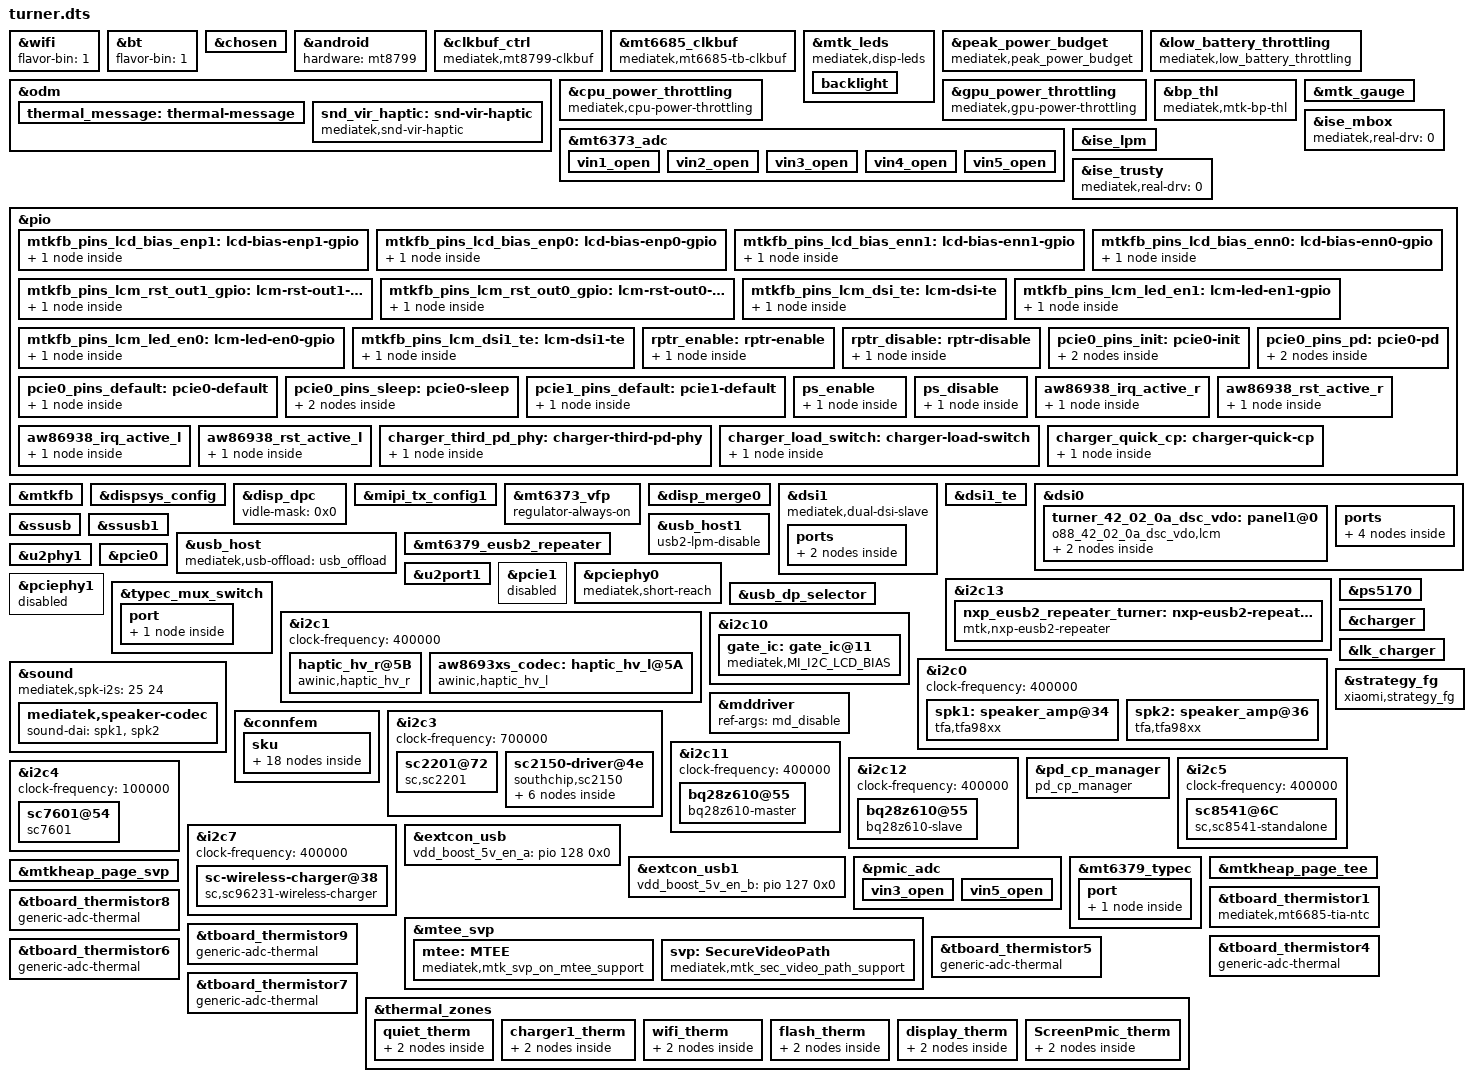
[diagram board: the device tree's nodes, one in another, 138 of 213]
// SPDX-License-Identifier: (GPL-2.0 OR MIT)
/*
 * Copyright (C) 2022 MediaTek Inc.
 */
/dts-v1/;
/plugin/;
&wifi {
	flavor-bin = "1";
};

&bt {
	flavor-bin = "1";
};

#include <dt-bindings/interrupt-controller/arm-gic.h>
#include <dt-bindings/interrupt-controller/irq.h>
#include <dt-bindings/phy/phy.h>
#include <dt-bindings/pinctrl/mt6991-pinfunc.h>
#include <dt-bindings/power/mt6991-power.h>
#include "mediatek/turner-mt6991-common.dtsi"
#include "mediatek/turner-sensor-common.dtsi"
#include <dt-bindings/iio/mt635x-auxadc.h>
#include <dt-bindings/thermal/thermal.h>
#include <dt-bindings/gpio/gpio.h>

&chosen {
bootargs_ext = "rcu_nocbs=0-7 \
		log_buf_len=4M";
bootargs_ext_fac = "cpufreq.default_governor=conservative \
		rcu_nocbs=0-7 \
		log_buf_len=4M";
};

&android {
	hardware = "mt8799";
};

&clkbuf_ctrl {
	compatible = "mediatek,mt8799-clkbuf";
};

&mt6685_clkbuf {
	compatible = "mediatek,mt6685-tb-clkbuf";
};

&mtk_leds {
	compatible = "mediatek,disp-leds";

	backlight {
		max-brightness = <4095>;
		min-brightness = <1>;
		max-hw-brightness = <2047>;
		led-mode = <4>;
		default-state = "FourteenPercent";
	};
};

&odm {
	thermal_message: thermal-message {
		board-sensor = "VIRTUAL-SENSOR";
		board-sensor-trip-enable = <1>;
		trip-point-high = <41000>;
		trip-point-low = <40000>;
	};
};

&peak_power_budget {
	compatible = "mediatek,peak_power_budget";

	battery-circult-rdc = <17>;
	battery0-path-rac-t0 = <35>;
	battery0-path-rac-t1 = <35>;
	battery0-path-rac-t2 = <35>;
	battery0-path-rac-t3 = <35>;
	battery0-path-rac-t4 = <35>;
	battery0-path-rac-t5 = <35>;

	system-uvlo = <2610>;

	max-temperature-stage = <5>;
	temperature-threshold = <25 10 0 0xFFFFFFF6 0xFFFFFFEC>;

	bat-ocv-table-num = <0>;
};

&low_battery_throttling {
		compatible = "mediatek,low_battery_throttling";
		lvsys-thd-enable = <1>;
		vbat-thd-enable = <1>;
		bat0-thd-volts-l = <
			3475 3200 3050
			3480 3200 3050
			3509 3200 3050
			3641 3200 3050
			3673 3200 3050>;
		bat0-thd-volts-h = <
			3575 3475 3200
			3580 3480 3200
			3609 3509 3200
			3741 3641 3200
			3773 3673 3200>;
		bat1-thd-volts-l = <
			3475 3200 3050
			3480 3200 3050
			3509 3200 3050
			3641 3200 3050
			3673 3200 3050>;
		bat1-thd-volts-h = <
			3575 3475 3200
			3580 3480 3200
			3609 3509 3200
			3741 3641 3200
			3773 3673 3200>;
		lvsys-thd-volt-l = <3050>;
		lvsys-thd-volt-h = <3200>;
		temperature-stage-threshold = <25 10 0 0xFFFFFFF6>;

		throttle-level = <0 1 2 3>,
			<0 1 2 3>,
			<0 1 2 3>,
			<0 1 2 3>,
			<0 1 2 3>;
};

&cpu_power_throttling {
	compatible = "mediatek,cpu-power-throttling";

	lbat-max-level = <3>;
	lbat-limit-freq-lv1 = < 1400000  1800000 2200000>;
	lbat-limit-freq-lv2 = < 1200000  120000  120000>;
	lbat-limit-freq-lv3 = < 330000   550000  670000>;

	oc-max-level = <2>;
	oc-limit-freq-lv1 = < 2147483647  2147483647 2147483647>;
	oc-limit-freq-lv2 = < 1200000  1700000 1900000>;

	soc-max-level = <3>;
	soc-core-active-lv1 = < 1 1 1 1 1 1 1 1 >;
	soc-core-active-lv2 = < 1 1 1 1 1 1 1 1 >;
	soc-core-active-lv3 = < 1 1 1 1 1 1 0 0 >;
	soc-limit-freq-lv1 = < 2147483647  2147483647 2147483647 >;
	soc-limit-freq-lv2 = < 1400000 1800000 2200000>;
	soc-limit-freq-lv3 = < 1800000 900000  670000>;
};

&gpu_power_throttling {
	compatible = "mediatek,gpu-power-throttling";

	lbat-max-level = <3>;
	lbat-limit-freq-lv1 = <754000>;
	lbat-limit-freq-lv2 = <754000>;
	lbat-limit-freq-lv3 = <338000>;

	oc-max-level = <2>;
	oc-limit-freq-lv1 = <988000>;
	oc-limit-freq-lv2 = <572000>;

	soc-max-level = <3>;
	soc-limit-freq-lv1 = <2147483647>;
	soc-limit-freq-lv2 = <754000>;
	soc-limit-freq-lv3 = <338000>;
};

&bp_thl{
	compatible = "mediatek,mtk-bp-thl";

	max-throttle-level = <3>;
	soc-throttle-level = <0 1 1 2>, //temperature stage 0
					<0 1 1 2>, //temperature stage 1
					<0 1 1 2>, //temperature stage 2
					<0 1 3 3>; //temperature stage 3

	soc-max-stage = <3>;
	soc-limit-threshold = <15 7 5>;

	temperature-max-stage = <3>;
	temperature-stage-threshold = <25 10 0>;

	md-soc-throttle-l = <20>;
	md-soc-throttle-h = <25>;
};

&mtk_gauge {
	DISABLE_MTKBATTERY = <(1)>;
	FIXED_BATTERY_TEMPERATURE = <25>;
	#include "turner_mt6991_battery_table.dtsi"
};

&mt6373_adc {
	vin1_open {
		channel = <AUXADC_VIN1>;
		pures = <ADC_PURES_100K>;
	};
	vin2_open {
		channel = <AUXADC_VIN2>;
		pures = <ADC_PURES_100K>;
	};
	vin3_open {
		channel = <AUXADC_VIN3>;
		pures = <ADC_PURES_100K>;
	};
	vin4_open {
		channel = <AUXADC_VIN4>;
		pures = <ADC_PURES_100K>;
	};
	vin5_open {
		channel = <AUXADC_VIN5>;
		pures = <ADC_PURES_100K>;
	};
};

&ise_mbox {
	mediatek,real-drv = <0>;
};

&ise_lpm {
	ise-wakelock = <0>;
	ise-lpm-freerun = <0>;
	ise-lpm-deinit-bypass = <0>;
};

&ise_trusty {
	mediatek,real-drv = <0>;
};

&pio {
	mtkfb_pins_lcd_bias_enp1: lcd-bias-enp1-gpio {
		pins-cmd-dat {
			pinmux = <PINMUX_GPIO103__FUNC_GPIO103>;
			slew-rate = <1>;
			output-high;
		};
	};

	mtkfb_pins_lcd_bias_enp0: lcd-bias-enp0-gpio {
		pins-cmd-dat {
			pinmux = <PINMUX_GPIO103__FUNC_GPIO103>;
			slew-rate = <1>;
			output-low;
		};
	};

	mtkfb_pins_lcd_bias_enn1: lcd-bias-enn1-gpio {
		pins-cmd-dat {
			pinmux = <PINMUX_GPIO103__FUNC_GPIO103>;
			slew-rate = <1>;
			output-high;
		};
	};

	mtkfb_pins_lcd_bias_enn0: lcd-bias-enn0-gpio {
		pins-cmd-dat {
			pinmux = <PINMUX_GPIO103__FUNC_GPIO103>;
			slew-rate = <1>;
			output-low;
		};
	};

	mtkfb_pins_lcm_rst_out1_gpio: lcm-rst-out1-gpio {
		pins-cmd-dat {
			pinmux = <PINMUX_GPIO90__FUNC_GPIO90>;
			slew-rate = <1>;
			output-high;
		};
	};

	mtkfb_pins_lcm_rst_out0_gpio: lcm-rst-out0-gpio {
		pins-cmd-dat {
			pinmux = <PINMUX_GPIO90__FUNC_GPIO90>;
			slew-rate = <1>;
			output-low;
		};
	};
	mtkfb_pins_lcm_dsi_te: lcm-dsi-te {
		pins-cmd-dat {
			pinmux = <PINMUX_GPIO89__FUNC_DSI_TE>;
		};
	};

	mtkfb_pins_lcm_led_en1: lcm-led-en1-gpio {
		pins-cmd-dat {
			pinmux = <PINMUX_GPIO174__FUNC_GPIO174>;
			slew-rate = <1>;
			output-high;
		};
	};

	mtkfb_pins_lcm_led_en0: lcm-led-en0-gpio {
		pins-cmd-dat {
			pinmux = <PINMUX_GPIO174__FUNC_GPIO174>;
			slew-rate = <1>;
			output-low;
		};
	};

	mtkfb_pins_lcm_dsi1_te: lcm-dsi1-te {
		pins-cmd-dat {
			pinmux = <PINMUX_GPIO6__FUNC_DSI1_TE>;
		};
	};
};

&mtkfb {
	pinctrl-names = "lcd_bias_enp1_gpio", "lcd_bias_enp0_gpio",
		"lcd_bias_enn1_gpio", "lcd_bias_enn0_gpio",
		"lcm_rst_out1_gpio", "lcm_rst_out0_gpio",
		"mode_te_te", "lcm_led_en1_gpio", "lcm_led_en0_gpio";
	pinctrl-0 = <&mtkfb_pins_lcd_bias_enp1>;
	pinctrl-1 = <&mtkfb_pins_lcd_bias_enp0>;
	pinctrl-2 = <&mtkfb_pins_lcd_bias_enn1>;
	pinctrl-3 = <&mtkfb_pins_lcd_bias_enn0>;
	pinctrl-4 = <&mtkfb_pins_lcm_rst_out1_gpio>;
	pinctrl-5 = <&mtkfb_pins_lcm_rst_out0_gpio>;
	pinctrl-6 = <&mtkfb_pins_lcm_dsi_te>;
	pinctrl-7 = <&mtkfb_pins_lcm_led_en1>;
	pinctrl-8 = <&mtkfb_pins_lcm_led_en0>;
	pinctrl-9 = <&mtkfb_pins_lcm_dsi1_te>;

	status = "okay";
};

&dispsys_config {
	pinctrl-names = "mode_te_te";
	pinctrl-0 = <&mtkfb_pins_lcm_dsi_te>;
	pinctrl-1 = <&mtkfb_pins_lcm_dsi1_te>;

	is-tablet;
	status = "okay";
	lk_mode_index = <0>;
//	enable-discrete-path = <1>;
	helper-value = <0>, /*MTK_DRM_OPT_STAGE*/
		<1>, /*MTK_DRM_OPT_USE_CMDQ*/
		<1>, /*MTK_DRM_OPT_USE_M4U*/
		<1>, /*MTK_DRM_OPT_MMQOS_SUPPORT*/
		<1>, /*MTK_DRM_OPT_MMDVFS_SUPPORT*/
		<0>, /*MTK_DRM_OPT_SODI_SUPPORT*/
		<1>, /*MTK_DRM_OPT_IDLE_MGR*/
		<0>, /*MTK_DRM_OPT_IDLEMGR_SWTCH_DECOUPLE*/
		<0>, /*MTK_DRM_OPT_IDLEMGR_BY_REPAINT*/
		<0>, /*MTK_DRM_OPT_IDLEMGR_ENTER_ULPS*/
		<0>, /*MTK_DRM_OPT_IDLEMGR_KEEP_LP11*/
		<0>, /*MTK_DRM_OPT_DYNAMIC_RDMA_GOLDEN_SETTING*/
		<1>, /*MTK_DRM_OPT_IDLEMGR_DISABLE_ROUTINE_IRQ*/
		<1>, /*MTK_DRM_OPT_IDLEMGR_ASYNC*/
		<0>, /*MTK_DRM_OPT_MET_LOG*/
		<1>, /*MTK_DRM_OPT_USE_PQ*/
		<1>, /*MTK_DRM_OPT_ESD_CHECK_RECOVERY*/
		<1>, /*MTK_DRM_OPT_ESD_CHECK_SWITCH*/
		<1>, /*MTK_DRM_OPT_PRESENT_FENCE*/
		<0>, /*MTK_DRM_OPT_RDMA_UNDERFLOW_AEE*/
		<1>, /*MTK_DRM_OPT_DSI_UNDERRUN_AEE*/
		<0>, /*MTK_DRM_OPT_ODDMR_UNDERRUN_AEE*/
		<1>, /*MTK_DRM_OPT_HRT*/
		<0>, /*MTK_DRM_OPT_HRT_MODE*/
		<0>, /*MTK_DRM_OPT_DELAYED_TRIGGER*/
		<0>, /*MTK_DRM_OPT_OVL_EXT_LAYER*/
		<0>, /*MTK_DRM_OPT_AOD*/
		<1>, /*MTK_DRM_OPT_RPO*/
		<1>, /*MTK_DRM_OPT_DUAL_PIPE*/
		<0>, /*MTK_DRM_OPT_DC_BY_HRT*/
		<1>, /*MTK_DRM_OPT_OVL_WCG*/
		<0>, /*MTK_DRM_OPT_OVL_SBCH*/
		<1>, /*MTK_DRM_OPT_COMMIT_NO_WAIT_VBLANK*/
		<0>, /*MTK_DRM_OPT_MET*/
		<0>, /*MTK_DRM_OPT_REG_PARSER_RAW_DUMP*/
		<0>, /*MTK_DRM_OPT_VP_PQ*/
		<0>, /*MTK_DRM_OPT_GAME_PQ*/
		<0>, /*MTK_DRM_OPT_MMPATH*/
		<0>, /*MTK_DRM_OPT_HBM*/
		<0>, /*MTK_DRM_OPT_VDS_PATH_SWITCH*/
		<0>, /*MTK_DRM_OPT_LAYER_REC*/
		<1>, /*MTK_DRM_OPT_CLEAR_LAYER*/
		<0>, /*MTK_DRM_OPT_LFR*/
		<0>, /*MTK_DRM_OPT_SF_PF*/
		<0>, /*MTK_DRM_OPT_DYN_MIPI_CHANGE*/
		<1>, /*MTK_DRM_OPT_PRIM_DUAL_PIPE*/
		<0>, /*MTK_DRM_OPT_MSYNC2_0*/
		<0>, /*MTK_DRM_OPT_MSYNC2_0_WAIT_EPT*/
		<1>, /*MTK_DRM_OPT_MML_PRIMARY*/
		<1>, /*MTK_DRM_OPT_MML_SUPPORT_CMD_MODE*/
		<1>, /*MTK_DRM_OPT_MML_PQ*/
		<1>, /*MTK_DRM_OPT_MML_IR*/
		<0>, /*MTK_DRM_OPT_DUAL_TE*/
		<0>, /*MTK_DRM_OPT_RES_SWITCH*/
		<1>, /*MTK_DRM_OPT_RES_SWITCH_ON_AP*/
		<0>, /*MTK_DRM_OPT_PREFETCH_TE*/
		<0>, /*MTK_DRM_OPT_VIDLE_APSRC_OFF*/
		<0>, /*MTK_DRM_OPT_VIDLE_DSI_PLL_OFF*/
		<0>, /*MTK_DRM_OPT_CHECK_TRIGGER_MERGE*/
		<0>, /*MTK_DRM_OPT_VIRTUAL_DISP*/
		<1>, /*MTK_DRM_OPT_OVL_BW_MONITOR*/
		<0>, /*MTK_DRM_OPT_GPU_CACHE*/
		<1>, /*MTK_DRM_OPT_SPHRT*/
		<0>, /*MTK_DRM_OPT_SDPA_OVL_SWITCH*/
		<1>, /*MTK_DRM_OPT_HRT_BY_LARB*/
		<0>, /*MTK_DRM_OPT_TILE_OVERHEAD*/
		<0>, /*MTK_DRM_OPT_VIDLE_TOP_EN*/
		<0>, /*MTK_DRM_OPT_VIDLE_MTCMOS_DT_EN*/
		<0>, /*MTK_DRM_OPT_VIDLE_MMINFRA_DT_EN*/
		<0>, /*MTK_DRM_OPT_VIDLE_DVFS_DT_EN*/
		<0>, /*MTK_DRM_OPT_VIDLE_QOS_DT_EN*/
		<0>, /*MTK_DRM_OPT_VIDLE_GCE_TS_EN*/
		<0>, /*MTK_DRM_OPT_VIDLE_FULL_SCENARIO*/
		<0>, /*MTK_DRM_OPT_DPC_PRE_TE_EN*/
		<1>, /*MTK_DRM_OPT_PARTIAL_UPDATE*/
		<0>, /*MTK_DRM_OPT_SLC_ALL_CACHE*/
		<1>, /*MTK_DRM_OPT_OVL_WCG_BY_COLOR_MODE*/
		<0>, /*"MTK_DRM_OPT_OVLSYS_CASCADE"*/
		<1>; /*MTK_DRM_OPT_LTPO_VM*/
};

&disp_dpc {
	vidle-mask = <0x0>;
};

&mipi_tx_config1 {
	status = "okay";
};

&mt6373_vfp {
	regulator-always-on;
};

&disp_merge0 {
	status = "okay";
};

&dsi1 {
	mediatek,dual-dsi-slave;
	status = "okay";
	ports {
		#address-cells = <1>;
		#size-cells = <0>;
		port@1 {
			reg = <1>;
			slave_in: endpoint {
				remote-endpoint = <&master_out>;
			};
		};
	};
};

&dsi1_te {
	interrupt-parent = <&pio>;
	interrupts = <6 1 6 1>;
	status = "okay";
};

&dsi0 {
	status = "okay";
	#address-cells = <1>;
	#size-cells = <0>;
	turner_42_02_0a_dsc_vdo: panel1@0 {
		compatible = "o88_42_02_0a_dsc_vdo,lcm";
		reg = <0>;
		reset-gpios = <&pio 90 0>;
		mi,esd-err-irq-gpio = <&pio 22 0x2002>;
		mi,esd-err-irq-gpio-second = <&pio 21 0x2002>;
		lane-swap-setting = <1 2 0 3 4 2>;
		pn-swap-setting = <1 1 1 1 1 1>;
		pinctrl-names = "default";
		vcn18io-supply = <&mt6373_vcn18io>;
		hw_en-gpios = <&pio 181 0>;
		bias_enp-gpios = <&pio 187 0>;
		bias_enn-gpios = <&pio 206 0>;
		lcm_id-gpios = <&pio 180 (GPIO_ACTIVE_HIGH | GPIO_PULL_UP)>;
		port {
			panel_in: endpoint {
				remote-endpoint = <&dsi_out>;
			};
		};
	};

	ports {
		#address-cells = <1>;
		#size-cells = <0>;
		port@0 {
			reg = <0>;
			dsi_out: endpoint {
				remote-endpoint = <&panel_in>;
			};
		};
		port@1 {
			reg = <1>;
			master_out: endpoint {
				remote-endpoint = <&slave_in>;
			};
		};
	};
};

&pio {

	rptr_enable: rptr-enable {
		pins-cmd-dat {
			pinmux = <PINMUX_GPIO28__FUNC_GPIO28>;
			output-high;
		};
	};

	rptr_disable: rptr-disable {
		pins-cmd-dat {
			pinmux = <PINMUX_GPIO28__FUNC_GPIO28>;
			output-low;
		};
	};

};

&ssusb {
	mediatek,force-vbus;
	mediatek,clk-mgr;
	mediatek,usb3-drd;
	mediatek,uds = <&usb_dp_selector 19>;
	mediatek,eusb2-cm-l1 = <0x474>;
	maximum-speed = "super-speed";
	maximum-speed-host = <0x05>;
	usb-role-switch;
	status = "okay";
};

&ssusb1 {
	wakeup-source;
	mediatek,clk-mgr;
	mediatek,force-vbus;
	mediatek,eusb2-cm-l1 = <0x474>;
	maximum-speed = "high-speed";
	usb-role-switch;
	status = "okay";
};

&usb_host {
	mediatek,usb-offload = <&usb_offload>;
	status = "okay";
};

&usb_host1 {
	usb2-lpm-disable;
	status = "okay";
};

&mt6379_eusb2_repeater {
	mediatek,vrt-sel = <0>;
	mediatek,intr-ofs = "0";
	mediatek,term-ofs = "0";
	mediatek,equalization = <4>;
	mediatek,rx-sqth = <5>;
	mediatek,discth = <0xf>;
	mediatek,host-vrt-sel = <2>;
	mediatek,host-rx-sqth = <0>;
	mediatek,host-discth = <0xf>;
	mediatek,host-term-ofs = "-3";
	mediatek,host-intr-ofs = "4";
	mediatek,pre-emphasis = <2>;
	status = "okay";
};


&i2c13 {

	nxp_eusb2_repeater_turner: nxp-eusb2-repeater-turner@43 {
		compatible = "mtk,nxp-eusb2-repeater";
		pinctrl-names = "enable", "disable";
		pinctrl-0 = <&rptr_enable>;
		pinctrl-1 = <&rptr_disable>;
		reg = <0x43>;
		#phy-cells = <0>;
		status = "okay";
	};

};

&nxp_eusb2_repeater_turner {
	mediatek,rptr-ouput-swing = <0x4>;
	mediatek,rptr-demphasis = <0x22>;
};

&u2phy1 {
	phy-cells = <1>;
	phys = <&nxp_eusb2_repeater_turner>;
	status = "okay";

};

&u2port1 {

	status = "okay";

};

&pcie0 {
	pinctrl-names = "init", "default", "sleep", "pd";
	pinctrl-0 = <&pcie0_pins_init>;
	pinctrl-1 = <&pcie0_pins_default>;
	pinctrl-2 = <&pcie0_pins_sleep>;
	pinctrl-3 = <&pcie0_pins_pd>;
	max-link-speed = <4>;
	status = "okay";
};

&pcie1 {
	pinctrl-names = "default";
	pinctrl-0 = <&pcie1_pins_default>;
	max-link-speed = <4>;
	status = "disabled";
};

&pciephy0 {
	mediatek,short-reach;
	status = "okay";
};

&pciephy1 {
	status = "disabled";
};

/* PCIe pinmux start */
/* skyhawk use waken to control DFD_EN, PCIe0 don't need to control it */
&pio {
	pcie0_pins_init: pcie0-init {
		pins-cmd-dat {
			pinmux = <PINMUX_GPIO241__FUNC_GPIO241>;
			output-low;
		};

		pins-cmd-dat1 {
			pinmux = <PINMUX_GPIO243__FUNC_GPIO243>;
			bias-pull-up;
			input-enable;
		};
	};

	pcie0_pins_default: pcie0-default {
		pins-cmd-dat {
			pinmux = <PINMUX_GPIO241__FUNC_PCIE_PERSTN>,
				 <PINMUX_GPIO243__FUNC_PCIE_CLKREQN>;
			bias-pull-up;
		};
	};

	pcie0_pins_sleep: pcie0-sleep {
		pins-cmd-dat {
			pinmux = <PINMUX_GPIO241__FUNC_GPIO241>;
			output-low;
		};

		pins-cmd-dat1 {
			pinmux = <PINMUX_GPIO243__FUNC_GPIO243>;
			bias-pull-up;
			input-enable;
		};
	};

	pcie0_pins_pd: pcie0-pd {
		pins-cmd-dat {
			pinmux = <PINMUX_GPIO241__FUNC_GPIO241>;
			output-low;
		};

		pins-cmd-dat1 {
			pinmux = <PINMUX_GPIO243__FUNC_GPIO243>;
			bias-pull-down;
			input-enable;
		};
	};

	pcie1_pins_default: pcie1-default {
		pins-cmd-dat {
			pinmux = <PINMUX_GPIO145__FUNC_PCIE_WAKEN_1P>,
				 <PINMUX_GPIO146__FUNC_PCIE_PERSTN_1P>,
				 <PINMUX_GPIO147__FUNC_PCIE_CLKREQN_1P>;
			bias-pull-up = <MTK_PUPD_SET_R1R0_01>;
		};
	};
};
/* PCIe pinmux end */

#if 0
/* no need set here, 6686 will control elna automatically */
/* GPS GPIO standardization start */
&pio {
	gps_pins_default: gps_default {
	};
	gps_l1_lna_pins_ol: gps-l1-lna0 {
		pins-cmd-dat {
			pinmux = <PINMUX_GPIO12__FUNC_GPIO12>;
			output-low;
		};
	};
	gps_l1_lna_pins_dsp_ctrl: gps-l1-lna1 {
		pins-cmd-dat {
			pinmux = <PINMUX_GPIO12__FUNC_GPS_L1_ELNA_EN>;
		};
	};
	gps_l1_lna_pins_oh: gps-l1-lna2 {
		pins-cmd-dat {
			pinmux = <PINMUX_GPIO12__FUNC_GPIO12>;
			output-high;
		};
	};
	gps_l5_lna_pins_ol: gps-l5-lna0 {
		pins-cmd-dat {
			pinmux = <PINMUX_GPIO13__FUNC_GPIO13>;
			output-low;
		};
	};
	gps_l5_lna_pins_dsp_ctrl: gps-l5-lna1 {
		pins-cmd-dat {
			pinmux = <PINMUX_GPIO13__FUNC_GPS_L5_ELNA_EN>;
		};
	};
	gps_l5_lna_pins_oh: gps-l5-lna2 {
		pins-cmd-dat {
			pinmux = <PINMUX_GPIO13__FUNC_GPIO13>;
			output-high;
		};
	};
};
&gps {
	pinctrl-names = "default",
		"gps_l1_lna_disable",
		"gps_l1_lna_dsp_ctrl",
		"gps_l1_lna_enable",
		"gps_l5_lna_disable",
		"gps_l5_lna_dsp_ctrl",
		"gps_l5_lna_enable";
	pinctrl-0 = <&gps_pins_default>;
	pinctrl-1 = <&gps_l1_lna_pins_ol>;
	pinctrl-2 = <&gps_l1_lna_pins_dsp_ctrl>;
	pinctrl-3 = <&gps_l1_lna_pins_oh>;
	pinctrl-4 = <&gps_l5_lna_pins_ol>;
	pinctrl-5 = <&gps_l5_lna_pins_dsp_ctrl>;
	pinctrl-6 = <&gps_l5_lna_pins_oh>;
	status = "okay";
};
/* GPS GPIO standardization end */
#endif

/* usb typec mux start */
&pio {

	ps_enable: ps_enable {
		pins-cmd-dat {
			pinmux = <PINMUX_GPIO207__FUNC_GPIO207>;
			output-high;
		};
	};

	ps_disable: ps_disable {
		pins-cmd-dat {
			pinmux = <PINMUX_GPIO207__FUNC_GPIO207>;
			output-low;
		};
	};

};

&typec_mux_switch {
	orientation-switch;
	mode-switch;
	accessory;
	port {
		ssusb_mux: endpoint {
			remote-endpoint = <&tcpc_typec_usb>;
		};
	};
};

&ps5170 {
	pinctrl-names = "enable", "disable";
	pinctrl-0 = <&ps_enable>;
	pinctrl-1 = <&ps_disable>;
	status = "okay";
};

&usb_dp_selector {
	status = "okay";
};
/* usb typec mux end */

&pio {
	aw86938_irq_active_r:aw86938_irq_active_r {
		pins_cmd_dat {
			pinmux = <PINMUX_GPIO5__FUNC_GPIO5>;
			slew-rate = <0>;
			bias-pull-up = <00>;
		};
	};
	aw86938_rst_active_r:aw86938_rst_active_r {
		pins_cmd_dat {
			pinmux = <PINMUX_GPIO42__FUNC_GPIO42>;
			slew-rate = <0>;
			bias-pull-up = <00>;
		};
	};
	aw86938_irq_active_l:aw86938_irq_active_l {
		pins_cmd_dat {
			pinmux = <PINMUX_GPIO11__FUNC_GPIO11>;
			slew-rate = <0>;
			bias-pull-up = <00>;
		};
	};
	aw86938_rst_active_l:aw86938_rst_active_l {
		pins_cmd_dat {
			pinmux = <PINMUX_GPIO41__FUNC_GPIO41>;
			slew-rate = <0>;
			bias-pull-up = <00>;
		};
	};
};

&i2c1 {
    clock-frequency = <400000>;
	status = "ok";
	haptic_hv_r@5B {
		compatible = "awinic,haptic_hv_r";
		reg = <0x5B>;
		#sound-dai-cells = <0>;
		sound-name-prefix = "HAPTIC_SPK_R";
		irq-gpio = <&pio 11 1>;
		reset-gpio = <&pio 41 1>;
		f0_pre = < 1700 >;
		mode = /bits/ 8 < 5 >;
		aw8693x_f0_cali_percent = /bits/ 8 < 15 >;
		aw8693x_gain_bypass = /bits/ 8 < 1 >;
		aw8693x_uvlo_vol_default = /bits/ 8 < 0 >;
		aw8693x_cont_smart_loop = /bits/ 8 < 0 >;
		aw8693x_cont_drv1_lvl = /bits/ 8 < 0x7F >;
		aw8693x_cont_drv2_lvl = /bits/ 8 < 0x38 >;
		aw8693x_cont_lra_vrms = < 1000 >;
		aw8693x_cont_drv1_time = /bits/ 8 < 0x04 >;
		aw8693x_cont_drv2_time = /bits/ 8 < 0x32 >;
		aw8693x_cont_track_margin = /bits/ 8 < 0x0F >;
		aw8693x_cont_brk_gain = /bits/ 8 < 0x08 >;
		aw8693x_cont_brk_time = /bits/ 8 < 0x08 >;
		aw8693x_duration_time = /bits/ 8 < 20 30 60 >;
		aw8693x_d2s_gain = /bits/ 8 < 0x04 >;
		aw8693x_algo_d2s_gain = /bits/ 8 < 0x01 >;
		aw8693x_drv_width = /bits/ 8 < 0x6A >;
		aw8693x_trig_config = /bits/ 8 < 0 0 0 1 0 2 0 0
						 0 0 0 1 0 2 0 0
						 0 0 0 1 0 2 0 0 >;
		aw8693x_bst_vol_default = < 8500 >;
		/* aw8693x_is_enabled_track_en; */
		aw8693x_vib_effect_max = < 197 >; /*vib_effect_max must bigger than vib_effect_id*/
		/* aw8693x_is_enabled_auto_bst; */
		/* aw8693x_is_enabled_one_wire; */
	};
	aw8693xs_codec: haptic_hv_l@5A{
		status = "ok";
		compatible = "awinic,haptic_hv_l";
		reg = <0x5A>;
		#sound-dai-cells = <0>;
		sound-name-prefix = "HAPTIC_SPK";
		f0_pre = < 1700 >;
		mode = /bits/ 8 < 5 >;
		irq-gpio = <&pio 5 1>;
		reset-gpio = <&pio 42 1>;
		/****************** aw8693x **************/
		aw8693x_f0_cali_percent = /bits/ 8 < 15 >;
		aw8693x_gain_bypass = /bits/ 8 < 1 >;
		aw8693x_uvlo_vol_default = /bits/ 8 < 0 >;
		aw8693x_cont_smart_loop = /bits/ 8 < 0 >;
		aw8693x_cont_drv1_lvl = /bits/ 8 < 0x7F >;
		aw8693x_cont_drv2_lvl = /bits/ 8 < 0x38 >;
		aw8693x_cont_drv_width = /bits/ 8 <0x8A>;
		aw8693x_cont_lra_vrms = < 1000 >;
		aw8693x_cont_drv1_time = /bits/ 8 < 0x04 >;
		aw8693x_cont_drv2_time = /bits/ 8 < 0x32 >;
		aw8693x_cont_track_margin = /bits/ 8 < 0x0F >;
		aw8693x_cont_brk_gain = /bits/ 8 < 0x08 >;
		aw8693x_cont_brk_time = /bits/ 8 < 0x08 >;
		aw8693x_duration_time = /bits/ 8 < 20 30 60 >;
		aw8693x_d2s_gain = /bits/ 8 < 0x04 >;
		aw8693x_algo_d2s_gain = /bits/ 8 < 0x01 >;
		aw8693x_drv_width = /bits/ 8 < 0x6A >;
		aw8693x_trig_config = /bits/ 8 < 0 0 0 1 0 2 0 0
						 0 0 0 1 0 2 0 0
						 0 0 0 1 0 2 0 0 >;
		aw8693x_bst_vol_default = < 8500 >;
		/* aw8693x_is_enabled_track_en; */
		aw8693x_vib_effect_max = < 197 >; /*vib_effect_max must bigger than vib_effect_id*/
		/* aw8693x_is_enabled_auto_bst; */
		/* aw8693x_is_enabled_one_wire; */
	};
};

&i2c10 {
	gate_ic: gate_ic@11 {
		compatible = "mediatek,MI_I2C_LCD_BIAS";
		label = "lcd-backlight";
		pwm_config = <0 1 0 0 0>;
		reg = <0x11>;
		id = <10>;
		status = "okay";
	};
};

&i2c0 {
/*
	spk1: speaker_amp@5c {
		compatible = "richtek,rt5512";
		#sound-dai-cells = <0>;
		reg = <0x5c>;
		status = "okay";
		sound-name-prefix = "Left";
	};

	spk2: speaker_amp@5d {
		compatible = "richtek,rt5512";
		#sound-dai-cells = <0>;
		reg = <0x5d>;
		status = "okay";
		sound-name-prefix = "Right";
	};
*/
       clock-frequency = <400000>;
       spk1: speaker_amp@34 {
               status = "okay";
               compatible = "tfa,tfa98xx";
               #sound-dai-cells = <0>;
               reg = <0x34>;
               reset-gpio = <&pio 91 0>;
               reset-polarity=<0>;
               irq-gpio = <&pio 39 0>;
       };

       spk2: speaker_amp@36 {
               status = "okay";
               compatible = "tfa,tfa98xx";
               #sound-dai-cells = <0>;
               reg = <0x36>;
               reset-polarity=<0>;
               irq-gpio = <&pio 94 0>;
       };
};

&sound {
	mediatek,spk-i2s = <25 24>;
	mediatek,speaker-codec {
		sound-dai = <&spk1>, <&spk2>;
	};
};

&odm {
	snd_vir_haptic: snd-vir-haptic {
		compatible = "mediatek,snd-vir-haptic";
	};
};

&mddriver {
	ref-args = "md_disable";
};

#if 0
&pdc {
	pd_vbus_upper_bound = <12000000>;
};
#endif

&connfem {
	sku {
		hw-names =
			"qm42655_qm45655",	/* [0] QM42655/QM45655, 2G+2A+1A, BT AntSwap */
			"qm42655_qm45655_2g2a",	/* [1] QM42655/QM45655, 2G+2A */
			"sky55208_sky55714";	/* [2] SKY55208/SKY55714, 2G+2A+1A, BT AntSwap */

		/***************************************************************
		 * [HW][0] QM42655/QM45655, 2G+2A+1A, BT AntSwap
		 **************************************************************/
		hw-0 {
			using-fems =
				<&qm42655>,
				<&qm45655>;

			layout-flag = <0x00000000>;
			layout =
				<&g_wf0_bt0_qm42655>,
				<&g_wf1_bt1_qm42655>,
				<&a_wf0_qm45655>,
				<&a_wf1_qm45655>,
				<&a_wf2_bt0_qm45655>;

			layout-spdt =
				<&spdt_a2_filter>,
				<&spdt_g_bt1_antswap>;

			common {
				flags {
					fe-ant-cnt = [85];
					fe-conn-dpdt-sp3t = [80];
					fe-conn-spdt = [88];
					fe-bt-wf-usage = [98];
					fe-conn-spdt-2 = [80];
				};
			};

			wifi {
				using-states =
					<&qm42655_rxl>,
					<&qm45655_rxl>;
			};

			bt {
				flags {
					efem-mode = [03]; /* 3:epa_elna, 2:epa, 1:elna, 0:bypass */
					rx-mode = [34]; /* 0x34: G-band RxL, HBBT RxH */
				};
			};
		};

		/***************************************************************
		 * [HW][1] QM42655/QM45655, 2G+2A
		 **************************************************************/
		hw-1 {
			using-fems =
				<&qm42655>,
				<&qm45655>;

			layout-flag = <0x00000000>;
			layout =
				<&g_wf0_bt0_qm42655>,
				<&g_wf1_bt1_qm42655>,
				<&a_wf0_qm45655>,
				<&a_wf1_qm45655>;

			common {
				flags {
					fe-ant-cnt = [85];
					fe-conn-dpdt-sp3t = [80];
					fe-conn-spdt = [80];
					fe-bt-wf-usage = [80];
					fe-conn-spdt-2 = [80];
				};
			};

			wifi {
				using-states =
					<&qm42655_rxl>,
					<&qm45655_rxl>;
			};

			bt {
				flags {
					efem-mode = [03]; /* 3:epa_elna, 2:epa, 1:elna, 0:bypass */
					rx-mode = [24]; /* 0x24: G-band RxL */
				};
			};
		};

		/***************************************************************
		 * [HW][2] SKY55208/SKY55714, 2G+2A+1A, BT AntSwap
		 **************************************************************/
		hw-2 {
			using-fems =
				<&sky55208>,
				<&sky55714>;

			layout-flag = <0x00000000>;
			layout =
				<&g_wf0_bt0_sky55208>,
				<&g_wf1_bt1_sky55208>,
				<&a_wf0_sky55714>,
				<&a_wf1_sky55714>,
				<&a_wf2_bt0_sky55714>;

			layout-spdt =
				<&spdt_a2_filter>,
				<&spdt_g_bt1_antswap>;

			common {
				flags {
					fe-ant-cnt = [96];
					fe-conn-dpdt-sp3t = [80];
					fe-conn-spdt = [98];
					fe-bt-wf-usage = [98];
					fe-conn-spdt-2 = [80];
				};
			};

			wifi {
				using-states =
					<&sky55208_rxl>,
					<&sky55714_rxl>;
			};

			bt {
				flags {
					efem-mode = [03]; /* 3:epa_elna, 2:epa, 1:elna, 0:bypass */
					rx-mode = [34]; /* 0x34: G-band RxL, HBBT RxH */
				};
			};
		};
	};
};

&i2c3 {
    status = "okay";
    clock-frequency = <700000>;
	sc2201@72 {
        compatible = "sc,sc2201";
        reg = <0x72>;
        sc2201,intr-gpio = <&pio 111 IRQ_TYPE_EDGE_FALLING>;
        sc2201,reset-gpio = <&pio 193 0x0>;
        sc,sc2201,wd_timeout = <0>;
        sc,sc2201,dpdm_en = <0>;
	phys = <&u2port1 PHY_TYPE_USB2>;
	phy-names = "usb2-phy";
	usb = <&ssusb>;
	pinctrl-names = "charger_third_pd_phy";
 	pinctrl-0 = <&charger_third_pd_phy>;
    };

	sc2150-driver@4e{
		compatible = "southchip,sc2150";
		reg = <0x4E>;
		status = "okay";
		sc-tcpc,name = "type_c_port1"; /* tcpc_device's name */
		sc-tcpc,role_def = <5>; /* 0: Unknown, 1: SNK, 2: SRC */
					/* 3: DRP, 4: Try.SRC, 5: Try.SNK */
		sc-tcpc,rp_level = <1>; /* 0: Default, 1: 1.5, 2: 3.0 */
		sc-tcpc,vconn_supply  = <1>;  /* 0: Never, 1: Always, */
					      /* 2: EMarkOnly, 3: StartOnly */
		sc-tcpc,notifier_supply_num = <2>;
		sc2150,intr-gpio = <&pio 43 IRQ_TYPE_EDGE_FALLING>;
		cid_detin_b = <&pio 23 IRQ_TYPE_EDGE_BOTH>;
		pd-data {
			pd,vid = <0x2717>;
			pd,pid = <0x209e>;
			pd,source-cap-ext = /bits/ 8 <0x17 0x27 0x9e 0x20
						      0x00 0x00 0x00 0x00
						      0x00 0x00 0x00 0x00
						      0x00 0x00 0x00 0x00
						      0x00 0x00 0x00 0x00
						      0x00 0x00 0x01 0x05
						      0x00>;
			pd,sink-cap-ext = /bits/ 8 <0x17 0x27 0x9e 0x20
							   0x00 0x00 0x00 0x00
							   0x01 0x00 0x00 0x00
							   0x00 0x00 0x00 0x00
							   0x01 0x00 0x00 0x00
							   0x00 0x00 0x00 0x00>;
			pd,mfrs = "SouthChip";

			/*
			 *	VSAFE5V = 0, MAX_POWER = 1, CUSTOM = 2,
			 *	MAX_POWER_LV = 0x21, MAX_POWER_LVIC = 0x31
			 *	MAX_POWER_HV = 0x41, MAX_POWER_HVIC = 0x51
			 */
			pd,charging_policy= <0x31>;

			/*
			 * Fixed 5V, 500 mA <0x00019032>
			 * Fixed 5V, 1A <0x00019064>
			 * Fixed 5V, 2A <0x000190c8>
			 * Fixed 5V, 3A <0x0001912c>
			 * Fixed 9V, 500 mA <0x0002d032>
			 * Fixed 9V, 1A <0x0002d064>
			 * Fixed 9V, 2A <0x0002d0c8>
			 * Fixed 9V, 3A <0x0002d12c>
			 * Variable 5-9V, 1A <0x8642d064>
			 * Variable 5-9V, 2A <0x8642d0c8>
			 * Variable 5-9V, 3A <0x8642d12c>
			 * PPS 3V~5.9V, 3A <0xC0761E3C>
			 */
			pd,source-pdo-size = <1>;
			/* Fixed 5V,1A */
			pd,source-pdo-data = <0x36019064>;
			pd,sink-pdo-size = <1>;
			pd,sink-pdo-data = <0x260190c8>;
			/*0110 1110 0011 0010
			 * No DP, host + device
			 *	pd,id-vdo-size = <6>;
			 *	pd,id-vdo-data = <0xd1402717 0x0 0x17110000
						  0x61000000 0x0 0x41000000>;
			 * With DP
			 *	pd,id-vdo-size = <6>;
			 *	pd,id-vdo-data = <0xd54029cf 0x0 0x17110000
						  0x61000000 0x0 0x41000000>;
			 */

			pd,id-vdo-size = <4>;
			pd,id-vdo-data = <0x81402717 0x0 0x209e0200 0x41000000>;

			bat,nr = <1>;
			pd,country_nr = <0>;

			bat-info0 {
				bat,vid = <0x2717>;
				bat,pid = <0x209e>;
				bat,mfrs = "bat1";
				bat,design_cap = <3000>;
			};

		};
		dpm_caps {
			local_dr_power;
			local_dr_data;
			//local_ext_power;
			local_usb_comm;
			//local_usb_suspend;
			//local_high_cap;
			//local_give_back;
			local_no_suspend;
			local_vconn_supply;

			//attempt_discover_cable_dfp;
			//attempt_enter_dp_mode;
			attempt_discover_cable;
			attempt_discover_id;
			attempt_discover_svid;

			/* 0: disable, 1: prefer_snk, 2: prefer_src */
			pr_check = <0>;
			//pr_reject_as_source;
			//pr_reject_as_sink;
			//pr_check_gp_source;
			//pr_check_gp_sink;

			/* 0: disable, 1: prefer_ufp, 2: prefer_dfp */
			dr_check = <0>;
			//dr_reject_as_dfp;
			dr_reject_as_ufp;
		};
		displayport {
			/* connection type = "both", "ufp_d", "dfp_d" */
			1st_connection = "dfp_d";
			2nd_connection = "dfp_d";
			signal,dp_v13;
			//signal,dp_gen2;
			//usbr20_not_used;
			typec,receptacle;
			ufp_d {
				//pin_assignment,mode_a;
				//pin_assignment,mode_b;
				//pin_assignment,mode_c;
				//pin_assignment,mode_d;
				//pin_assignment,mode_e;
			};
			dfp_d {
				//pin_assignment,mode_a;
				//pin_assignment,mode_b;
				pin_assignment,mode_c;
				pin_assignment,mode_d;
				pin_assignment,mode_e;
				//pin_assignment,mode_f;
			};
		};
	};
};

&i2c11 {
	clock-frequency = <400000>;
	status = "okay";
	bq28z610@55 {
		compatible = "bq28z610-master";
		reg = <0x55>;
		enable_shutdown_delay;
		max_chg_power_120w;
		normal_shutdown_vbat_1s = <3200>;
		critical_shutdown_vbat_1s = <3250>;
		cool_critical_shutdown_vbat_1s = <3250>;
		old_critical_shutdown_vbat_1s = <3250>;
		report_full_rsoc_1s = <9500>;
		soc_gap_1s = <2>;
		ic_role = <0>;
		batt1_ctrl_gpio = <&pio 130 0x0>;
		batt2_ctrl_gpio = <&pio 129 0x0>;
		/*pinctrl-names = "slave_connect_cfg";*/
		/*pinctrl-0 = <&slave_connect_cfg>;*/
		fgvio28-supply = <&mt6373_vio28>;
		soc_decimal_rate = <
			0  38
			10 35
			20 33
			30 33
			40 33
			50 33
			60 33
			70 30
			80 25
			90 20
			95 10 >;
	};
};

&i2c12 {
	clock-frequency = <400000>;
	status = "okay";
	bq28z610@55 {
		compatible = "bq28z610-slave";
		reg = <0x55>;
		enable_shutdown_delay;
		max_chg_power_120w;
		normal_shutdown_vbat_1s = <3200>;
		critical_shutdown_vbat_1s = <2960>;
		cool_critical_shutdown_vbat_1s = <2940>;
		old_critical_shutdown_vbat_1s = <2940>;
		report_full_rsoc_1s = <9500>;
		soc_gap_1s = <2>;
		ic_role = <1>;
		batt1_ctrl_gpio = <&pio 130 0x0>;
		batt2_ctrl_gpio = <&pio 129 0x0>;
		fgvio28-supply = <&mt6373_vio28>;
		/*pinctrl-names = "slave_connect_cfg";*/
		/*pinctrl-0 = <&slave_connect_cfg>;*/
		soc_decimal_rate = <
			0  38
			10 35
			20 33
			30 33
			40 33
			50 33
			60 33
			70 30
			80 25
			90 20
			95 10 >;
	};
};

&charger {
		max_charger_voltage = <12000000>;
		/* charging current */
		usb_charger_current = <500000>;
		ac_charger_current = <1600000>;
		ac_charger_input_current = <1600000>;
		charging_host_charger_current = <900000>;
		step_fallback_hyst = <25>;
		step_forward_hyst = <5>;
		jeita_fallback_hyst = <10>;
		jeita_forward_hyst = <10>;
		mt6373_moscon1_control;
		mt6373_moscon2_control;
		en_floatgnd;
		rust_support;
		pd2_input_current = <1700000>;
		min_charger_voltage_1 = <4600000>;
		min_charger_voltage_2 = <4500000>;
		sbu_uart_en = <&pio 24 0x0>;
		ffc_low_tbat = <150>;
		ffc_medium_tbat = <300>;
		ffc_warm_tbat = <350>;
		ffc_little_high_tbat = <400>;
		ffc_high_tbat = <480>;
		ffc_high_soc = <95>;
		adapter_power = <66>;
		enable_pdtest_mode = <1>;

		/* CN battery paremeter */
		fv = <4530>;
		fv_normal = <4510>;
		fv_ffc = <4580>;
		iterm = <210>;
		iterm_warm = <210>;
		slave_batt_iterm = <185>;
		slave_batt_iterm_warm = <185>;
		wlschg_chip_vendor = <2>;
		jeita_fcc_cfg = <(-100)	0	4200	739	739
				1	50	4200	1478	1478
				51	100	4200	3500	3500
				101	150	4200	5650	5650
				151	470	4200	12400	12400
				471	600	4100	3695	3695>;
		jeita_fv_cfg = <(-100)	0	4530
				1	50	4530
				51	100	4530
				101	150	4530
				151	470	4580
				471	600	4100>;

		flip_jeita_fv_cfg = <(-100)	0	4530
				1	50	4530
				51	100	4530
				101	150	4530
				151	470	4580
				471	600	4100>;
		flip_jeita_fcc_cfg = <(-100)	0	4200	345	345
				1	50	4200	690	690
				51	100	4200	1680	1680
				101	150	4200	2610	2610
				151	470	4200	7000	7000
				471	600	4100	1725	1725>;
		flip_step_chg_cfg_1_cycle = <3000	4130	7000
					4131	4350	5600
					4351	4400	3450
					4401	4530	3450
					4531	4580	2760>;
		flip_step_chg_cfg_100_cycle = <3000	4100	7000
					4101	4350	5600
					4351	4400	3450
					4401	4530	3450
					4531	4560	2760>;

		flip_step_chg_cfg_300_cycle = <3000	4100	7000
					4101	4350	5600
					4351	4400	3450
					4401	4510	3450
					4511	4540	2760>;

		flip_step_chg_cfg_800_cycle = <3000	4100	5600
					4101	4350	4480
					4351	4400	2760
					4401	4510	2760
					4511	4530	2210>;

		flip_step_chg_cfg_1000_cycle = <3000	4100	5600
					4101	4350	4480
					4351	4400	2760
					4401	4510	2760
					4511	4530	2210>;

		/* 1-100cls */
		step_chg_cfg_1_cycle = <3000	4130	12400
					4131	4350	11200
					4351	4400	7390
					4401	4530	7390
					4531	4580	5912>;
		iterm_ffc_1_cycle = <1700>;
		iterm_ffc_little_warm_1_cycle = <1700>;
		iterm_ffc_warm_1_cycle = <2111>;
		iterm_ffc_hot_1_cycle = <2111>;

		slave_batt_iterm_ffc_1_cycle = <1400>;
		slave_batt_iterm_ffc_little_warm_1_cycle = <1400>;
		slave_batt_iterm_ffc_warm_1_cycle = <1775>;
		slave_batt_iterm_ffc_hot_1_cycle = <1775>;

		/* 100-300cls */
		step_chg_cfg_100_cycle = <3000	4100	12400
					4101	4350	11200
					4351	4400	7390
					4401	4530	7390
					4531	4560	5912>;
		iterm_ffc_100_cycle = <1700>;
		iterm_ffc_little_warm_100_cycle = <1700>;
		iterm_ffc_warm_100_cycle = <2111>;
		iterm_ffc_hot_100_cycle = <2111>;

		slave_batt_iterm_ffc_100_cycle = <1400>;
		slave_batt_iterm_ffc_little_warm_100_cycle = <1400>;
		slave_batt_iterm_ffc_warm_100_cycle = <1775>;
		slave_batt_iterm_ffc_hot_100_cycle = <1775>;

		/* 300-800cls */
		step_chg_cfg_300_cycle = <3000	4100	12400
					4101	4350	11200
					4351	4400	7390
					4401	4510	7390
					4511	4540	5912>;
		iterm_ffc_300_cycle = <1700>;
		iterm_ffc_little_warm_300_cycle = <1700>;
		iterm_ffc_warm_300_cycle = <2111>;
		iterm_ffc_hot_300_cycle = <2111>;

		slave_batt_iterm_ffc_300_cycle = <1400>;
		slave_batt_iterm_ffc_little_warm_300_cycle = <1400>;
		slave_batt_iterm_ffc_warm_300_cycle = <1775>;
		slave_batt_iterm_ffc_hot_300_cycle = <1775>;

		/* 800-1000cls */
		step_chg_cfg_800_cycle = <3000	4100	11200
					4101	4350	8960
					4351	4400	5912
					4401	4510	5912
					4511	4530	4732>;
		iterm_ffc_800_cycle = <1700>;
		iterm_ffc_little_warm_800_cycle = <1700>;
		iterm_ffc_warm_800_cycle = <2111>;
		iterm_ffc_hot_800_cycle = <2111>;

		slave_batt_iterm_ffc_800_cycle = <1400>;
		slave_batt_iterm_ffc_little_warm_800_cycle = <1400>;
		slave_batt_iterm_ffc_warm_800_cycle = <1775>;
		slave_batt_iterm_ffc_hot_800_cycle = <1775>;

		/* >1000cls */
		step_chg_cfg_1000_cycle = <3000	4100	11200
					4101	4350	8960
					4351	4400	5912
					4401	4510	5912
					4511	4530	4732>;
		iterm_ffc_1000_cycle = <1700>;
		iterm_ffc_little_warm_1000_cycle = <1700>;
		iterm_ffc_warm_1000_cycle = <2111>;
		iterm_ffc_hot_1000_cycle = <2111>;

		slave_batt_iterm_ffc_1000_cycle = <1400>;
		slave_batt_iterm_ffc_little_warm_1000_cycle = <1400>;
		slave_batt_iterm_ffc_warm_1000_cycle = <1775>;
		slave_batt_iterm_ffc_hot_1000_cycle = <1775>;

		thermal_limit_dcp = <1900 1900 1900 1900 1900 1900 1900 1900 1900 1900 1900 1900 1500 1400 1200 1000>;
		thermal_limit_qc2 = <2500 2500 2500 2500 2500 2500 2500 2500 2500 2500 2500 2000 1500 1500 1000 500>;
		thermal_limit_qc3_18w = <2500 2500 2500 2500 2500 2500 2400 2300 2200 2100 1500 1000 800 700 600 500>;
		thermal_limit_qc3_27w = <2500 2500 2500 2500 2500 2500 2400 2300 2200 2100 1500 1000 800 700 600 500>;
		thermal_limit_qc35 = <2500 2500 2500 2500 2500 2500 2400 2300 2200 2100 1500 1000 800 700 600 500>;
		thermal_limit_pd = <12400 10500 9000 8000 7000 6200 5500 5000 4400 3600 3000 2500 2000 1500 1000 500>;

		smart_bypass_support;
		smart_bypass_entry_soc = <20>;
		smart_bypass_exit_soc = <90>;
		smart_bypass_fallback_hyst = <5>; // board_temp(0.1 degree) hyst
		smart_bypass_forward_hyst = <5>;
		smart_bypass_high_lmt_cfg = <(-100)	250	3000
				251	280	2500
				281	300	2000
				301	330	1600
				331	370	1200
				371	800	900>;
		smart_bypass_med_lmt_cfg = <(-100)	150	12400
				151	200	12400
				201	250	12400
				251	300	6200
				301	370	4400
				371	800	2000>;
		smart_bypass_low_lmt_cfg = <(-100)	150	12400
				151	200	12400
				201	250	12400
				251	300	12400
				301	370	12400
				371	800	12400>;
};

&lk_charger {
	/* charging current */
	usb-charger-current = <500000>;
	ac-charger-current = <1500000>;
	ac-charger-input-current = <2000000>;
	non-std-ac-charger-current = <1500000>;
	charging-host-charger-current = <1500000>;
	ta-ac-charger-current = <1500000>;
	pd-charger-current = <1500000>;
	/* battery temperature protection */
	temp-t4-threshold = <60>;
	temp-t3-threshold = <45>;
	pre-charger-current = <550000>;
	fast-charge-voltage = <3100>;
	max-charger-voltage = <12000000>;
	shutdown-voltage = <3200>;
	boot-battery-voltage = <3400000>;
};


&pd_cp_manager {
		compatible = "pd_cp_manager";
		fv = <4530>;
		fv_ffc = <4580>;
		max_fcc = <12400>;
		max_vbus = <12000>;
		max_ibus = <6200>;
		fcc_low_hyst = <120>;
		fcc_high_hyst = <(-30)>;
		low_tbat = <100>;
		high_tbat = <480>;
		high_vbat = <4400>;
		high_soc = <95>;
		low_fcc = <2000>;
		cv_vbat = <4510>;
		cv_vbat_ffc = <4560>;
		cv_ibat = <2000>;
		min_pdo_vbus = <8000>;
		max_pdo_vbus = <11000>;
		support_pmic_parachg;
		switch1_1_enter = <3100>;
		switch1_1_exit = <4100>;
		switch2_1_enter = <4500>;
		switch2_1_exit = <12500>;
		pdm_ibus_gap = <1600>;
		pdm_bypass_ibus_gap = <2600>;
		adapter_power = <66>;
		fv_hyst = <3>;
};

&strategy_fg{
		compatible = "xiaomi,strategy_fg";
		enable_shutdown_delay;
		normal_shutdown_vbat_1s = <3200>;
		critical_shutdown_vbat_1s = <3250>;
		cool_critical_shutdown_vbat_1s = <3250>;
		old_critical_shutdown_vbat_1s = <3250>;
		report_full_rsoc_1s = <9700>;
		soc_gap_1s = <2>;
		fg_type = <1>;
};

&mtk_gauge{
	DISABLE_MTKBATTERY = <(1)>;
};

&i2c5 {
	clock-frequency = <400000>;
	status = "okay";
	sc8541@6C{
		compatible = "sc,sc8541-standalone";
		reg = <0x6C>;
		pinctrl-names = "charger_quick_cp";
 		pinctrl-0 = <&charger_quick_cp>;
		interrupt-parent = <&pio>;
		interrupts = <76 0>;
		sc8541,intr_gpio = <&pio 27 IRQ_TYPE_EDGE_FALLING>;
		charger_name = "primary_dvchg";
		charger_name_v4_19 = "primary_divider_chg";
		sc,sc8541,vbat-ovp-dis = <0>;
		sc,sc8541,vbat-ovp = <90>; /*3840 + val * 10*/
		sc,sc8541,vbat-ovp-alm-dis = <1>;
		sc,sc8541,vbat-ovp-alm = <70>; /*3840 + val * 10*/
		sc,sc8541,ibat-ocp-dis = <0>;
		sc,sc8541,ibat-ocp  = <127>; /*val * 100*/
		sc,sc8541,ibat-ocp-alm-dis = <1>;
		sc,sc8541,ibat-ocp-alm = <80>; /*val * 100*/
		sc,sc8541,ibus-ucp-dis = <0>;
		sc,sc8541,vbus-in-range-dis = <0>;
		sc,sc8541,vbus-pd-en = <0>;
		sc,sc8541,vbus-ovp = <80>; /*7000 + val * 50*/
		sc,sc8541,vbus-ovp-alm-dis = <1>;
		sc,sc8541,vbus-ovp-alm = <80>; /*7000 + val * 50*/
		sc,sc8541,ibus-ocp-dis = <0>;
		sc,sc8541,ibus-ocp = <21>; /*1000 + val * 250*/
		sc,sc8541,tshut-dis = <1>;
		sc,sc8541,tsbus-flt-dis = <1>;
		sc,sc8541,tsbat-flt-dis = <1>;
		sc,sc8541,tdie-alm = <200>; /*25 + val * 0.5*/
		sc,sc8541,tsbus-flt = <21>;
		sc,sc8541,tsbat-flt = <21>;
		sc,sc8541,vac1-ovp = <3>; /*0:6.5V 1:10.5V 2:12V 3:14V 4:16V 5~7:18V*/
		sc,sc8541,vac2-ovp = <3>; /*0:6.5V 1:10.5V 2:12V 3:14V 4:16V 5~7:18V*/
		sc,sc8541,vac1-pd-en = <0>;
		sc,sc8541,vac2-pd-en = <0>;
		sc,sc8541,fsw-set = <4>; /*0:200KHz 1:300KHz 2:400KHz
				3:500KHz 4:600KHz 5:650KHz 6:700KHz 7:750KHz*/
		sc,sc8541,wd-timeout = <0>; /*0:0.5s 1:1s 2:5s 3:30s*/
		sc,sc8541,wd-timeout-dis = <1>;
		sc,sc8541,ibat-sns-r = <0>; /*0:2mho 1:5mho*/
		sc,sc8541,ss-timeout = <7>; /*0:6.25ms 1:12.5ms 2:25ms 3:50ms
				4:100ms 5:400ms 6:1.5s 7:10s*/
		sc,sc8541,ibus-ucp-fall-dg = <1>;
		sc,sc8541,vout-ovp-dis = <0>;
		sc,sc8541,vout-ovp = <3>; /*4700 + val * 100*/
		sc,sc8541,pmid2out-uvp = <7>; /*50 + val * 25*/
		sc,sc8541,pmid2out-ovp = <7>; /*200 + val * 50*/
		project_vendor = <2>;
	};
};

&i2c4 {
	clock-frequency = <100000>;
	status = "okay";
	sc7601@54 {
		compatible = "sc7601";
		ic_role = <0>;
		reg = <0x54>;
		bat-ovp-threshold = <5500>;
		pre-chg-curr = <100>;
		vfc-chg-volt = <3100>;
		limit-chg-curr = <2950>;
		pinctrl-names = "charger_load_switch";
 		pinctrl-0 = <&charger_load_switch>;
	};
};

&i2c7 {
    clock-frequency = <400000>;
    sc-wireless-charger@38{
        compatible = "sc,sc96231-wireless-charger";
        reg = <0x38>;
		project_vendor = <2>;
		fw_version_index = <0>;
		rx-int = <&pio 213 IRQ_TYPE_EDGE_FALLING>;
		hall-int3 = <&pio 211 IRQ_TYPE_EDGE_FALLING>;
		hall-int4 = <&pio 113 IRQ_TYPE_EDGE_FALLING>;
		hall-int3-s = <&pio 209 IRQ_TYPE_EDGE_FALLING>;
		hall-int4-s = <&pio 112 IRQ_TYPE_EDGE_FALLING>;
		reverse-boost-gpio = <&pio 212 0x0>;
		reverse-txon-gpio = <&pio 1 0x0>;
    };
};

&extcon_usb {
	vdd_boost_5v_en_a = <&pio 128 0x0>;
};

&extcon_usb1 {
	vdd_boost_5v_en_b = <&pio 127 0x0>;
	status = "okay";
};

&pmic_adc {
	vin3_open {
		channel = <AUXADC_VIN3>;
		pures = <ADC_PURES_100K>;
	};
	vin5_open {
		channel = <AUXADC_VIN5>;
		pures = <ADC_PURES_100K>;
	};
};

&mt6379_typec {
	tcpc,en_floatgnd;
	/* 0:16x, 1:128x, 2:512x, 3:1024x */
	wd,wd0_tsleep = <1>;
	/* 0:400us, 1:1ms, 2:2ms, 3:4ms, 4:10ms, 5:40ms, 6:100ms, 7:400ms */
	wd,wd0_tdet = <3>;
	/* example wd0_tsleep = 512x, wd0_tdet = 4ms, wd0 polling time = 512*4ms */

	port {
		tcpc_typec_usb: endpoint {
			remote-endpoint = <&ssusb_mux>;
		};
	};
};

&mtee_svp {
        mtee: MTEE {
                compatible = "mediatek,mtk_svp_on_mtee_support";
        };

        svp: SecureVideoPath {
                compatible = "mediatek,mtk_sec_video_path_support";
        };
};

&mtkheap_page_tee {
        status = "ok";
};

&mtkheap_page_svp {
        status = "ok";
};

&tboard_thermistor1 {
	compatible = "mediatek,mt6685-tia-ntc";
	#thermal-sensor-cells = <0>;
	reg = <0 0x1c01d128 0 0x4>; /* TIA DATA T0 */
	temperature-lookup-table =
			<(-40000) 4397119>,
			<(-39000) 4092874>,
			<(-38000) 3811717>,
			<(-37000) 3551749>,
			<(-36000) 3311236>,
			<(-35000) 3088599>,
			<(-34000) 2882396>,
			<(-33000) 2691310>,
			<(-32000) 2514137>,
			<(-31000) 2349778>,
			<(-30000) 2197225>,
			<(-29000) 2055558>,
			<(-28000) 1923932>,
			<(-27000) 1801573>,
			<(-26000) 1687773>,
			<(-25000) 1581881>,
			<(-24000) 1483100>,
			<(-23000) 1391113>,
			<(-22000) 1305413>,
			<(-21000) 1225531>,
			<(-20000) 1151037>,
			<(-19000) 1081535>,
			<(-18000) 1016661>,
			<(-17000) 956080>,
			<(-16000) 899481>,
			<(-15000) 846579>,
			<(-14000) 797111>,
			<(-13000) 750834>,
			<(-12000) 707524>,
			<(-11000) 666972>,
			<(-10000) 628988>,
			<(-9000) 593342>,
			<(-8000) 559931>,
			<(-7000) 528602>,
			<(-6000) 499212>,
			<(-5000) 471632>,
			<(-4000) 445772>,
			<(-3000) 421480>,
			<(-2000) 398652>,
			<(-1000) 377193>,
			<0 357012>,
			<1000 338006>,
			<2000 320122>,
			<3000 303287>,
			<4000 287434>,
			<5000 272500>,
			<6000 258426>,
			<7000 245160>,
			<8000 232649>,
			<9000 220847>,
			<10000 209710>,
			<11000 199196>,
			<12000 189268>,
			<13000 179890>,
			<14000 171027>,
			<15000 162651>,
			<16000 154726>,
			<17000 147232>,
			<18000 140142>,
			<19000 133432>,
			<20000 127080>,
			<21000 121066>,
			<22000 115368>,
			<23000 109970>,
			<24000 104852>,
			<25000 100000>,
			<26000 95398>,
			<27000 91032>,
			<28000 86889>,
			<29000 82956>,
			<30000 79222>,
			<31000 75675>,
			<32000 72306>,
			<33000 69104>,
			<34000 66061>,
			<35000 63167>,
			<36000 60415>,
			<37000 57797>,
			<38000 55306>,
			<39000 52934>,
			<40000 50677>,
			<41000 48528>,
			<42000 46482>,
			<43000 44533>,
			<44000 42675>,
			<45000 40904>,
			<46000 39213>,
			<47000 37601>,
			<48000 36063>,
			<49000 34595>,
			<50000 33195>,
			<51000 31859>,
			<52000 30584>,
			<53000 29366>,
			<54000 28203>,
			<55000 27091>,
			<56000 26028>,
			<57000 25013>,
			<58000 24042>,
			<59000 23113>,
			<60000 22224>,
			<61000 21374>,
			<62000 20560>,
			<63000 19782>,
			<64000 19036>,
			<65000 18322>,
			<66000 17640>,
			<67000 16986>,
			<68000 16360>,
			<69000 15759>,
			<70000 15184>,
			<71000 14631>,
			<72000 14100>,
			<73000 13591>,
			<74000 13103>,
			<75000 12635>,
			<76000 12187>,
			<77000 11756>,
			<78000 11343>,
			<79000 10946>,
			<80000 10565>,
			<81000 10199>,
			<82000 9847>,
			<83000 9509>,
			<84000 9184>,
			<85000 8872>,
			<86000 8572>,
			<87000 8283>,
			<88000 8005>,
			<89000 7738>,
			<90000 7481>,
			<91000 7234>,
			<92000 6997>,
			<93000 6769>,
			<94000 6548>,
			<95000 6337>,
			<96000 6132>,
			<97000 5934>,
			<98000 5744>,
			<99000 5561>,
			<100000 5384>,
			<101000 5214>,
			<102000 5051>,
			<103000 4893>,
			<104000 4741>,
			<105000 4594>,
			<106000 4453>,
			<107000 4316>,
			<108000 4184>,
			<109000 4057>,
			<110000 3934>,
			<111000 3816>,
			<112000 3701>,
			<113000 3591>,
			<114000 3484>,
			<115000 3380>,
			<116000 3281>,
			<117000 3185>,
			<118000 3093>,
			<119000 3003>,
			<120000 2916>,
			<121000 2832>,
			<122000 2751>,
			<123000 2672>,
			<124000 2596>,
			<125000 2522>;
};

&tboard_thermistor8 {
	compatible = "generic-adc-thermal";
	#thermal-sensor-cells = <0>;
	io-channels = <&mt6373_adc AUXADC_VIN1>;
	io-channel-names = "sensor-channel";
	temperature-lookup-table =
			<(-40000) 1799>,
			<(-39000) 1796>,
			<(-38000) 1792>,
			<(-37000) 1789>,
			<(-36000) 1786>,
			<(-35000) 1782>,
			<(-34000) 1778>,
			<(-33000) 1774>,
			<(-32000) 1769>,
			<(-31000) 1764>,
			<(-30000) 1759>,
			<(-29000) 1754>,
			<(-28000) 1749>,
			<(-27000) 1743>,
			<(-26000) 1737>,
			<(-25000) 1730>,
			<(-24000) 1723>,
			<(-23000) 1716>,
			<(-22000) 1709>,
			<(-21000) 1701>,
			<(-20000) 1692>,
			<(-19000) 1684>,
			<(-18000) 1675>,
			<(-17000) 1665>,
			<(-16000) 1655>,
			<(-15000) 1645>,
			<(-14000) 1634>,
			<(-13000) 1623>,
			<(-12000) 1612>,
			<(-11000) 1600>,
			<(-10000) 1587>,
			<(-9000) 1574>,
			<(-8000) 1561>,
			<(-7000) 1547>,
			<(-6000) 1532>,
			<(-5000) 1518>,
			<(-4000) 1502>,
			<(-3000) 1487>,
			<(-2000) 1471>,
			<(-1000) 1454>,
			<0 1437>,
			<1000 1419>,
			<2000 1402>,
			<3000 1383>,
			<4000 1365>,
			<5000 1346>,
			<6000 1326>,
			<7000 1306>,
			<8000 1286>,
			<9000 1266>,
			<10000 1245>,
			<11000 1225>,
			<12000 1203>,
			<13000 1182>,
			<14000 1161>,
			<15000 1139>,
			<16000 1117>,
			<17000 1095>,
			<18000 1073>,
			<19000 1051>,
			<20000 1029>,
			<21000 1007>,
			<22000 985>,
			<23000 963>,
			<24000 941>,
			<25000 920>,
			<26000 898>,
			<27000 876>,
			<28000 855>,
			<29000 834>,
			<30000 813>,
			<31000 792>,
			<32000 772>,
			<33000 751>,
			<34000 731>,
			<35000 712>,
			<36000 692>,
			<37000 673>,
			<38000 655>,
			<39000 636>,
			<40000 618>,
			<41000 601>,
			<42000 583>,
			<43000 566>,
			<44000 550>,
			<45000 534>,
			<46000 518>,
			<47000 502>,
			<48000 487>,
			<49000 472>,
			<50000 458>,
			<51000 444>,
			<52000 430>,
			<53000 417>,
			<54000 404>,
			<55000 392>,
			<56000 380>,
			<57000 368>,
			<58000 356>,
			<59000 345>,
			<60000 334>,
			<61000 324>,
			<62000 313>,
			<63000 303>,
			<64000 294>,
			<65000 284>,
			<66000 275>,
			<67000 267>,
			<68000 258>,
			<69000 250>,
			<70000 242>,
			<71000 234>,
			<72000 227>,
			<73000 220>,
			<74000 213>,
			<75000 206>,
			<76000 199>,
			<77000 193>,
			<78000 187>,
			<79000 181>,
			<80000 175>,
			<81000 170>,
			<82000 164>,
			<83000 159>,
			<84000 154>,
			<85000 149>,
			<86000 145>,
			<87000 140>,
			<88000 136>,
			<89000 132>,
			<90000 128>,
			<91000 124>,
			<92000 120>,
			<93000 116>,
			<94000 113>,
			<95000 109>,
			<96000 106>,
			<97000 103>,
			<98000 99>,
			<99000 96>,
			<100000 94>,
			<101000 91>,
			<102000 88>,
			<103000 85>,
			<104000 83>,
			<105000 80>,
			<106000 78>,
			<107000 76>,
			<108000 73>,
			<109000 71>,
			<110000 69>,
			<111000 67>,
			<112000 65>,
			<113000 63>,
			<114000 61>,
			<115000 60>,
			<116000 58>,
			<117000 56>,
			<118000 55>,
			<119000 53>,
			<120000 52>,
			<121000 50>,
			<122000 49>,
			<123000 47>,
			<124000 46>,
			<125000 45>;
};

&tboard_thermistor9 {
	compatible = "generic-adc-thermal";
	#thermal-sensor-cells = <0>;
	io-channels = <&mt6373_adc AUXADC_VIN2>;
	io-channel-names = "sensor-channel";
	temperature-lookup-table =
			<(-40000) 1799>,
			<(-39000) 1796>,
			<(-38000) 1792>,
			<(-37000) 1789>,
			<(-36000) 1786>,
			<(-35000) 1782>,
			<(-34000) 1778>,
			<(-33000) 1774>,
			<(-32000) 1769>,
			<(-31000) 1764>,
			<(-30000) 1759>,
			<(-29000) 1754>,
			<(-28000) 1749>,
			<(-27000) 1743>,
			<(-26000) 1737>,
			<(-25000) 1730>,
			<(-24000) 1723>,
			<(-23000) 1716>,
			<(-22000) 1709>,
			<(-21000) 1701>,
			<(-20000) 1692>,
			<(-19000) 1684>,
			<(-18000) 1675>,
			<(-17000) 1665>,
			<(-16000) 1655>,
			<(-15000) 1645>,
			<(-14000) 1634>,
			<(-13000) 1623>,
			<(-12000) 1612>,
			<(-11000) 1600>,
			<(-10000) 1587>,
			<(-9000) 1574>,
			<(-8000) 1561>,
			<(-7000) 1547>,
			<(-6000) 1532>,
			<(-5000) 1518>,
			<(-4000) 1502>,
			<(-3000) 1487>,
			<(-2000) 1471>,
			<(-1000) 1454>,
			<0 1437>,
			<1000 1419>,
			<2000 1402>,
			<3000 1383>,
			<4000 1365>,
			<5000 1346>,
			<6000 1326>,
			<7000 1306>,
			<8000 1286>,
			<9000 1266>,
			<10000 1245>,
			<11000 1225>,
			<12000 1203>,
			<13000 1182>,
			<14000 1161>,
			<15000 1139>,
			<16000 1117>,
			<17000 1095>,
			<18000 1073>,
			<19000 1051>,
			<20000 1029>,
			<21000 1007>,
			<22000 985>,
			<23000 963>,
			<24000 941>,
			<25000 920>,
			<26000 898>,
			<27000 876>,
			<28000 855>,
			<29000 834>,
			<30000 813>,
			<31000 792>,
			<32000 772>,
			<33000 751>,
			<34000 731>,
			<35000 712>,
			<36000 692>,
			<37000 673>,
			<38000 655>,
			<39000 636>,
			<40000 618>,
			<41000 601>,
			<42000 583>,
			<43000 566>,
			<44000 550>,
			<45000 534>,
			<46000 518>,
			<47000 502>,
			<48000 487>,
			<49000 472>,
			<50000 458>,
			<51000 444>,
			<52000 430>,
			<53000 417>,
			<54000 404>,
			<55000 392>,
			<56000 380>,
			<57000 368>,
			<58000 356>,
			<59000 345>,
			<60000 334>,
			<61000 324>,
			<62000 313>,
			<63000 303>,
			<64000 294>,
			<65000 284>,
			<66000 275>,
			<67000 267>,
			<68000 258>,
			<69000 250>,
			<70000 242>,
			<71000 234>,
			<72000 227>,
			<73000 220>,
			<74000 213>,
			<75000 206>,
			<76000 199>,
			<77000 193>,
			<78000 187>,
			<79000 181>,
			<80000 175>,
			<81000 170>,
			<82000 164>,
			<83000 159>,
			<84000 154>,
			<85000 149>,
			<86000 145>,
			<87000 140>,
			<88000 136>,
			<89000 132>,
			<90000 128>,
			<91000 124>,
			<92000 120>,
			<93000 116>,
			<94000 113>,
			<95000 109>,
			<96000 106>,
			<97000 103>,
			<98000 99>,
			<99000 96>,
			<100000 94>,
			<101000 91>,
			<102000 88>,
			<103000 85>,
			<104000 83>,
			<105000 80>,
			<106000 78>,
			<107000 76>,
			<108000 73>,
			<109000 71>,
			<110000 69>,
			<111000 67>,
			<112000 65>,
			<113000 63>,
			<114000 61>,
			<115000 60>,
			<116000 58>,
			<117000 56>,
			<118000 55>,
			<119000 53>,
			<120000 52>,
			<121000 50>,
			<122000 49>,
			<123000 47>,
			<124000 46>,
			<125000 45>;
};

&tboard_thermistor4 {
	compatible = "generic-adc-thermal";
	#thermal-sensor-cells = <0>;
	io-channels = <&mt6373_adc AUXADC_VIN4>;
	io-channel-names = "sensor-channel";
	temperature-lookup-table =
			<(-40000) 1799>,
			<(-39000) 1796>,
			<(-38000) 1792>,
			<(-37000) 1789>,
			<(-36000) 1786>,
			<(-35000) 1782>,
			<(-34000) 1778>,
			<(-33000) 1774>,
			<(-32000) 1769>,
			<(-31000) 1764>,
			<(-30000) 1759>,
			<(-29000) 1754>,
			<(-28000) 1749>,
			<(-27000) 1743>,
			<(-26000) 1737>,
			<(-25000) 1730>,
			<(-24000) 1723>,
			<(-23000) 1716>,
			<(-22000) 1709>,
			<(-21000) 1701>,
			<(-20000) 1692>,
			<(-19000) 1684>,
			<(-18000) 1675>,
			<(-17000) 1665>,
			<(-16000) 1655>,
			<(-15000) 1645>,
			<(-14000) 1634>,
			<(-13000) 1623>,
			<(-12000) 1612>,
			<(-11000) 1600>,
			<(-10000) 1587>,
			<(-9000) 1574>,
			<(-8000) 1561>,
			<(-7000) 1547>,
			<(-6000) 1532>,
			<(-5000) 1518>,
			<(-4000) 1502>,
			<(-3000) 1487>,
			<(-2000) 1471>,
			<(-1000) 1454>,
			<0 1437>,
			<1000 1419>,
			<2000 1402>,
			<3000 1383>,
			<4000 1365>,
			<5000 1346>,
			<6000 1326>,
			<7000 1306>,
			<8000 1286>,
			<9000 1266>,
			<10000 1245>,
			<11000 1225>,
			<12000 1203>,
			<13000 1182>,
			<14000 1161>,
			<15000 1139>,
			<16000 1117>,
			<17000 1095>,
			<18000 1073>,
			<19000 1051>,
			<20000 1029>,
			<21000 1007>,
			<22000 985>,
			<23000 963>,
			<24000 941>,
			<25000 920>,
			<26000 898>,
			<27000 876>,
			<28000 855>,
			<29000 834>,
			<30000 813>,
			<31000 792>,
			<32000 772>,
			<33000 751>,
			<34000 731>,
			<35000 712>,
			<36000 692>,
			<37000 673>,
			<38000 655>,
			<39000 636>,
			<40000 618>,
			<41000 601>,
			<42000 583>,
			<43000 566>,
			<44000 550>,
			<45000 534>,
			<46000 518>,
			<47000 502>,
			<48000 487>,
			<49000 472>,
			<50000 458>,
			<51000 444>,
			<52000 430>,
			<53000 417>,
			<54000 404>,
			<55000 392>,
			<56000 380>,
			<57000 368>,
			<58000 356>,
			<59000 345>,
			<60000 334>,
			<61000 324>,
			<62000 313>,
			<63000 303>,
			<64000 294>,
			<65000 284>,
			<66000 275>,
			<67000 267>,
			<68000 258>,
			<69000 250>,
			<70000 242>,
			<71000 234>,
			<72000 227>,
			<73000 220>,
			<74000 213>,
			<75000 206>,
			<76000 199>,
			<77000 193>,
			<78000 187>,
			<79000 181>,
			<80000 175>,
			<81000 170>,
			<82000 164>,
			<83000 159>,
			<84000 154>,
			<85000 149>,
			<86000 145>,
			<87000 140>,
			<88000 136>,
			<89000 132>,
			<90000 128>,
			<91000 124>,
			<92000 120>,
			<93000 116>,
			<94000 113>,
			<95000 109>,
			<96000 106>,
			<97000 103>,
			<98000 99>,
			<99000 96>,
			<100000 94>,
			<101000 91>,
			<102000 88>,
			<103000 85>,
			<104000 83>,
			<105000 80>,
			<106000 78>,
			<107000 76>,
			<108000 73>,
			<109000 71>,
			<110000 69>,
			<111000 67>,
			<112000 65>,
			<113000 63>,
			<114000 61>,
			<115000 60>,
			<116000 58>,
			<117000 56>,
			<118000 55>,
			<119000 53>,
			<120000 52>,
			<121000 50>,
			<122000 49>,
			<123000 47>,
			<124000 46>,
			<125000 45>;
};

&tboard_thermistor5 {
	compatible = "generic-adc-thermal";
	#thermal-sensor-cells = <0>;
	io-channels = <&mt6373_adc AUXADC_VIN5>;
	io-channel-names = "sensor-channel";
	temperature-lookup-table =
			<(-40000) 1799>,
			<(-39000) 1796>,
			<(-38000) 1792>,
			<(-37000) 1789>,
			<(-36000) 1786>,
			<(-35000) 1782>,
			<(-34000) 1778>,
			<(-33000) 1774>,
			<(-32000) 1769>,
			<(-31000) 1764>,
			<(-30000) 1759>,
			<(-29000) 1754>,
			<(-28000) 1749>,
			<(-27000) 1743>,
			<(-26000) 1737>,
			<(-25000) 1730>,
			<(-24000) 1723>,
			<(-23000) 1716>,
			<(-22000) 1709>,
			<(-21000) 1701>,
			<(-20000) 1692>,
			<(-19000) 1684>,
			<(-18000) 1675>,
			<(-17000) 1665>,
			<(-16000) 1655>,
			<(-15000) 1645>,
			<(-14000) 1634>,
			<(-13000) 1623>,
			<(-12000) 1612>,
			<(-11000) 1600>,
			<(-10000) 1587>,
			<(-9000) 1574>,
			<(-8000) 1561>,
			<(-7000) 1547>,
			<(-6000) 1532>,
			<(-5000) 1518>,
			<(-4000) 1502>,
			<(-3000) 1487>,
			<(-2000) 1471>,
			<(-1000) 1454>,
			<0 1437>,
			<1000 1419>,
			<2000 1402>,
			<3000 1383>,
			<4000 1365>,
			<5000 1346>,
			<6000 1326>,
			<7000 1306>,
			<8000 1286>,
			<9000 1266>,
			<10000 1245>,
			<11000 1225>,
			<12000 1203>,
			<13000 1182>,
			<14000 1161>,
			<15000 1139>,
			<16000 1117>,
			<17000 1095>,
			<18000 1073>,
			<19000 1051>,
			<20000 1029>,
			<21000 1007>,
			<22000 985>,
			<23000 963>,
			<24000 941>,
			<25000 920>,
			<26000 898>,
			<27000 876>,
			<28000 855>,
			<29000 834>,
			<30000 813>,
			<31000 792>,
			<32000 772>,
			<33000 751>,
			<34000 731>,
			<35000 712>,
			<36000 692>,
			<37000 673>,
			<38000 655>,
			<39000 636>,
			<40000 618>,
			<41000 601>,
			<42000 583>,
			<43000 566>,
			<44000 550>,
			<45000 534>,
			<46000 518>,
			<47000 502>,
			<48000 487>,
			<49000 472>,
			<50000 458>,
			<51000 444>,
			<52000 430>,
			<53000 417>,
			<54000 404>,
			<55000 392>,
			<56000 380>,
			<57000 368>,
			<58000 356>,
			<59000 345>,
			<60000 334>,
			<61000 324>,
			<62000 313>,
			<63000 303>,
			<64000 294>,
			<65000 284>,
			<66000 275>,
			<67000 267>,
			<68000 258>,
			<69000 250>,
			<70000 242>,
			<71000 234>,
			<72000 227>,
			<73000 220>,
			<74000 213>,
			<75000 206>,
			<76000 199>,
			<77000 193>,
			<78000 187>,
			<79000 181>,
			<80000 175>,
			<81000 170>,
			<82000 164>,
			<83000 159>,
			<84000 154>,
			<85000 149>,
			<86000 145>,
			<87000 140>,
			<88000 136>,
			<89000 132>,
			<90000 128>,
			<91000 124>,
			<92000 120>,
			<93000 116>,
			<94000 113>,
			<95000 109>,
			<96000 106>,
			<97000 103>,
			<98000 99>,
			<99000 96>,
			<100000 94>,
			<101000 91>,
			<102000 88>,
			<103000 85>,
			<104000 83>,
			<105000 80>,
			<106000 78>,
			<107000 76>,
			<108000 73>,
			<109000 71>,
			<110000 69>,
			<111000 67>,
			<112000 65>,
			<113000 63>,
			<114000 61>,
			<115000 60>,
			<116000 58>,
			<117000 56>,
			<118000 55>,
			<119000 53>,
			<120000 52>,
			<121000 50>,
			<122000 49>,
			<123000 47>,
			<124000 46>,
			<125000 45>;
};

&tboard_thermistor6 {
	compatible = "generic-adc-thermal";
	#thermal-sensor-cells = <0>;
	io-channels = <&mt6373_adc AUXADC_VIN3>;
	io-channel-names = "sensor-channel";
	temperature-lookup-table =
			<(-40000) 1799>,
			<(-39000) 1796>,
			<(-38000) 1792>,
			<(-37000) 1789>,
			<(-36000) 1786>,
			<(-35000) 1782>,
			<(-34000) 1778>,
			<(-33000) 1774>,
			<(-32000) 1769>,
			<(-31000) 1764>,
			<(-30000) 1759>,
			<(-29000) 1754>,
			<(-28000) 1749>,
			<(-27000) 1743>,
			<(-26000) 1737>,
			<(-25000) 1730>,
			<(-24000) 1723>,
			<(-23000) 1716>,
			<(-22000) 1709>,
			<(-21000) 1701>,
			<(-20000) 1692>,
			<(-19000) 1684>,
			<(-18000) 1675>,
			<(-17000) 1665>,
			<(-16000) 1655>,
			<(-15000) 1645>,
			<(-14000) 1634>,
			<(-13000) 1623>,
			<(-12000) 1612>,
			<(-11000) 1600>,
			<(-10000) 1587>,
			<(-9000) 1574>,
			<(-8000) 1561>,
			<(-7000) 1547>,
			<(-6000) 1532>,
			<(-5000) 1518>,
			<(-4000) 1502>,
			<(-3000) 1487>,
			<(-2000) 1471>,
			<(-1000) 1454>,
			<0 1437>,
			<1000 1419>,
			<2000 1402>,
			<3000 1383>,
			<4000 1365>,
			<5000 1346>,
			<6000 1326>,
			<7000 1306>,
			<8000 1286>,
			<9000 1266>,
			<10000 1245>,
			<11000 1225>,
			<12000 1203>,
			<13000 1182>,
			<14000 1161>,
			<15000 1139>,
			<16000 1117>,
			<17000 1095>,
			<18000 1073>,
			<19000 1051>,
			<20000 1029>,
			<21000 1007>,
			<22000 985>,
			<23000 963>,
			<24000 941>,
			<25000 920>,
			<26000 898>,
			<27000 876>,
			<28000 855>,
			<29000 834>,
			<30000 813>,
			<31000 792>,
			<32000 772>,
			<33000 751>,
			<34000 731>,
			<35000 712>,
			<36000 692>,
			<37000 673>,
			<38000 655>,
			<39000 636>,
			<40000 618>,
			<41000 601>,
			<42000 583>,
			<43000 566>,
			<44000 550>,
			<45000 534>,
			<46000 518>,
			<47000 502>,
			<48000 487>,
			<49000 472>,
			<50000 458>,
			<51000 444>,
			<52000 430>,
			<53000 417>,
			<54000 404>,
			<55000 392>,
			<56000 380>,
			<57000 368>,
			<58000 356>,
			<59000 345>,
			<60000 334>,
			<61000 324>,
			<62000 313>,
			<63000 303>,
			<64000 294>,
			<65000 284>,
			<66000 275>,
			<67000 267>,
			<68000 258>,
			<69000 250>,
			<70000 242>,
			<71000 234>,
			<72000 227>,
			<73000 220>,
			<74000 213>,
			<75000 206>,
			<76000 199>,
			<77000 193>,
			<78000 187>,
			<79000 181>,
			<80000 175>,
			<81000 170>,
			<82000 164>,
			<83000 159>,
			<84000 154>,
			<85000 149>,
			<86000 145>,
			<87000 140>,
			<88000 136>,
			<89000 132>,
			<90000 128>,
			<91000 124>,
			<92000 120>,
			<93000 116>,
			<94000 113>,
			<95000 109>,
			<96000 106>,
			<97000 103>,
			<98000 99>,
			<99000 96>,
			<100000 94>,
			<101000 91>,
			<102000 88>,
			<103000 85>,
			<104000 83>,
			<105000 80>,
			<106000 78>,
			<107000 76>,
			<108000 73>,
			<109000 71>,
			<110000 69>,
			<111000 67>,
			<112000 65>,
			<113000 63>,
			<114000 61>,
			<115000 60>,
			<116000 58>,
			<117000 56>,
			<118000 55>,
			<119000 53>,
			<120000 52>,
			<121000 50>,
			<122000 49>,
			<123000 47>,
			<124000 46>,
			<125000 45>;
};

&tboard_thermistor7 {
	compatible = "generic-adc-thermal";
	#thermal-sensor-cells = <0>;
	io-channels = <&pmic_adc AUXADC_VIN5>;
	io-channel-names = "sensor-channel";
	temperature-lookup-table =
		<(-40000) 1799>,
		<(-39000) 1797>,
		<(-38000) 1794>,
		<(-37000) 1790>,
		<(-36000) 1787>,
		<(-35000) 1783>,
		<(-34000) 1779>,
		<(-33000) 1775>,
		<(-32000) 1771>,
		<(-31000) 1766>,
		<(-30000) 1761>,
		<(-29000) 1756>,
		<(-28000) 1751>,
		<(-27000) 1745>,
		<(-26000) 1739>,
		<(-25000) 1733>,
		<(-24000) 1726>,
		<(-23000) 1719>,
		<(-22000) 1712>,
		<(-21000) 1705>,
		<(-20000) 1696>,
		<(-19000) 1688>,
		<(-18000) 1678>,
		<(-17000) 1669>,
		<(-16000) 1659>,
		<(-15000) 1649>,
		<(-14000) 1640>,
		<(-13000) 1628>,
		<(-12000) 1617>,
		<(-11000) 1605>,
		<(-10000) 1592>,
		<(-9000) 1580>,
		<(-8000) 1567>,
		<(-7000) 1554>,
		<(-6000) 1539>,
		<(-5000) 1526>,
		<(-4000) 1509>,
		<(-3000) 1493>,
		<(-2000) 1477>,
		<(-1000) 1460>,
		<0 1445>,
		<1000 1427>,
		<2000 1409>,
		<3000 1391>,
		<4000 1373>,
		<5000 1354>,
		<6000 1335>,
		<7000 1314>,
		<8000 1295>,
		<9000 1276>,
		<10000 1255>,
		<11000 1233>,
		<12000 1212>,
		<13000 1190>,
		<14000 1169>,
		<15000 1147>,
		<16000 1125>,
		<17000 1104>,
		<18000 1082>,
		<19000 1059>,
		<20000 1039>,
		<21000 1016>,
		<22000 993>,
		<23000 971>,
		<24000 942>,
		<25000 920>,
		<26000 899>,
		<27000 878>,
		<28000 856>,
		<29000 835>,
		<30000 814>,
		<31000 794>,
		<32000 773>,
		<33000 753>,
		<34000 733>,
		<35000 714>,
		<36000 694>,
		<37000 676>,
		<38000 656>,
		<39000 638>,
		<40000 620>,
		<41000 602>,
		<42000 587>,
		<43000 570>,
		<44000 551>,
		<45000 534>,
		<46000 518>,
		<47000 503>,
		<48000 488>,
		<49000 473>,
		<50000 459>,
		<51000 444>,
		<52000 431>,
		<53000 417>,
		<54000 404>,
		<55000 392>,
		<56000 379>,
		<57000 368>,
		<58000 356>,
		<59000 345>,
		<60000 334>,
		<61000 323>,
		<62000 313>,
		<63000 303>,
		<64000 293>,
		<65000 284>,
		<66000 275>,
		<67000 266>,
		<68000 258>,
		<69000 250>,
		<70000 242>,
		<71000 234>,
		<72000 226>,
		<73000 219>,
		<74000 212>,
		<75000 206>,
		<76000 199>,
		<77000 193>,
		<78000 187>,
		<79000 181>,
		<80000 175>,
		<81000 169>,
		<82000 164>,
		<83000 159>,
		<84000 154>,
		<85000 149>,
		<86000 144>,
		<87000 140>,
		<88000 136>,
		<89000 131>,
		<90000 127>,
		<91000 123>,
		<92000 120>,
		<93000 116>,
		<94000 112>,
		<95000 109>,
		<96000 105>,
		<97000 102>,
		<98000 99>,
		<99000 96>,
		<100000 93>,
		<101000 90>,
		<102000 88>,
		<103000 85>,
		<104000 82>,
		<105000 80>,
		<106000 78>,
		<107000 75>,
		<108000 73>,
		<109000 71>,
		<110000 69>,
		<111000 67>,
		<112000 65>,
		<113000 63>,
		<114000 61>,
		<115000 59>,
		<116000 58>,
		<117000 56>,
		<118000 55>,
		<119000 53>,
		<120000 51>,
		<121000 50>,
		<122000 49>,
		<123000 47>,
		<124000 46>,
		<125000 45>;
};

&thermal_zones {
	quiet_therm: quiet_therm {
		polling-delay = <0>; /* milliseconds */
		polling-delay-passive = <0>; /* milliseconds */
		thermal-sensors = <&tboard_thermistor8>;

		trips {
			quiet_therm_crit: quiet-therm-crit {
				temperature = <119000>;
				hysteresis = <2000>;
				type = "passive";
			};
		};
	};
	charger1_therm: charger1_therm {
		polling-delay = <0>; /* milliseconds */
		polling-delay-passive = <0>; /* milliseconds */
		thermal-sensors = <&tboard_thermistor9>;

		trips {
			charger1_therm_crit: charger1-therm-crit {
				temperature = <119000>;
				hysteresis = <2000>;
				type = "passive";
			};
		};
	};
	wifi_therm: wifi_therm {
		polling-delay = <0>; /* milliseconds */
		polling-delay-passive = <0>; /* milliseconds */
		thermal-sensors = <&tboard_thermistor4>;

		trips {
			wifi_therm_crit: wifi-therm-crit {
				temperature = <119000>;
				hysteresis = <2000>;
				type = "passive";
			};
		};
	};
	flash_therm: flash_therm {
		polling-delay = <0>; /* milliseconds */
		polling-delay-passive = <0>; /* milliseconds */
		thermal-sensors = <&tboard_thermistor5>;

		trips {
			flash_therm_crit: flash-therm-crit {
				temperature = <119000>;
				hysteresis = <2000>;
				type = "passive";
			};
		};
	};
	display_therm: display_therm {
		polling-delay = <0>; /* milliseconds */
		polling-delay-passive = <0>; /* milliseconds */
		thermal-sensors = <&tboard_thermistor6>;

		trips {
			display_therm_crit: display-therm-crit {
				temperature = <119000>;
				hysteresis = <2000>;
				type = "passive";
			};
		};
	};
	ScreenPmic_therm: ScreenPmic_therm {
		polling-delay = <0>; /* milliseconds */
		polling-delay-passive = <0>; /* milliseconds */
		thermal-sensors = <&tboard_thermistor7>;

		trips {
			ScreenPmic_therm_crit: ScreenPmic-therm-crit {
				temperature = <119000>;
				hysteresis = <2000>;
				type = "passive";
			};
		};
	};
};

&pio {
	charger_third_pd_phy: charger-third-pd-phy {
 		pins_cmd_dat {
 			pinmux = <PINMUX_GPIO123__FUNC_SCL3>,
  			<PINMUX_GPIO124__FUNC_SDA3>;
 			bias-pull-up = <MTK_PULL_SET_RSEL_111>;
 		};
 	};
};

&pio {
	charger_load_switch: charger-load-switch {
 		pins_cmd_dat {
 			pinmux = <PINMUX_GPIO190__FUNC_SCL4>,
			<PINMUX_GPIO191__FUNC_SDA4>;
 			bias-pull-up = <MTK_PULL_SET_RSEL_101>;
 		};
 	};
};

&pio {
	charger_quick_cp: charger-quick-cp {
 		pins_cmd_dat {
 			pinmux = <PINMUX_GPIO176__FUNC_SCL5>,
			<PINMUX_GPIO177__FUNC_SDA5>;
 			bias-pull-up = <MTK_PULL_SET_RSEL_111>;
 		};
 	};
};

#include <turner/cust.dtsi>
#include "mediatek/cust_k6991_connfem.dtsi"

#include "mediatek/xiaomi_turner_mt8799_touch.dtsi"
#include "mediatek/xiaomi_turner_mt6991_mitee.dtsi"
#include "mediatek/turner_mt6991_camera_v4l2.dtsi"
#include "mediatek/xiaomi_mt6991_wifi.dtsi"
/*End of this file, DO NOT ADD ANYTHING HERE*/

